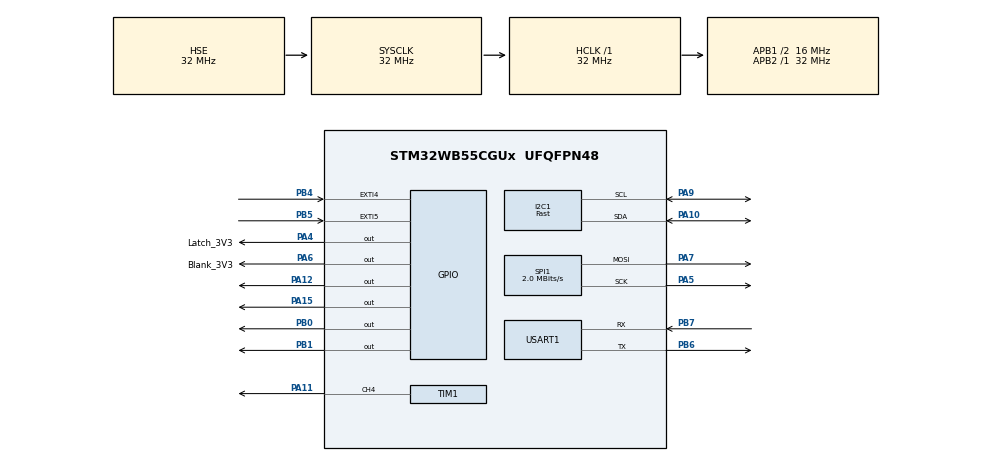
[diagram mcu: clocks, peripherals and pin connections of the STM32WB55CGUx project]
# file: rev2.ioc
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I2C1.I2C_Speed_Mode=I2C_Fast
I2C1.Timing=0x0010061A
LPTIM1.ClockPrescaler=LPTIM_PRESCALER_DIV128
Mcu.Family=STM32WB
Mcu.Name=STM32WB55CGUx
Mcu.Package=UFQFPN48
NVIC.EXTI4_IRQn=true\:0\:0\:false\:false\:true\:true\:true
NVIC.EXTI9_5_IRQn=true\:0\:0\:false\:false\:true\:true\:true
NVIC.HSEM_IRQn=true\:0\:0\:false\:false\:true\:false\:true
NVIC.I2C1_ER_IRQn=true\:0\:0\:false\:false\:true\:true\:true
NVIC.I2C1_EV_IRQn=true\:0\:0\:false\:false\:true\:true\:true
NVIC.IPCC_C1_RX_IRQn=true\:0\:0\:false\:false\:true\:true\:true
NVIC.IPCC_C1_TX_IRQn=true\:0\:0\:false\:false\:true\:true\:true
NVIC.LPTIM1_IRQn=true\:1\:0\:true\:false\:true\:true\:true
NVIC.LPTIM2_IRQn=true\:0\:0\:false\:false\:true\:true\:true
NVIC.PriorityGroup=NVIC_PRIORITYGROUP_4
NVIC.RTC_Alarm_IRQn=true\:0\:0\:false\:false\:true\:true\:true
NVIC.RTC_WKUP_IRQn=true\:0\:0\:false\:false\:true\:true\:true
NVIC.SPI1_IRQn=true\:0\:0\:false\:false\:true\:true\:true
NVIC.TIM1_TRG_COM_TIM17_IRQn=true\:0\:0\:false\:false\:true\:true\:true
NVIC.TIM1_UP_TIM16_IRQn=true\:0\:0\:false\:false\:true\:true\:true
NVIC.TIM2_IRQn=true\:0\:0\:false\:false\:true\:true\:true
NVIC.USART1_IRQn=true\:0\:0\:false\:false\:true\:true\:true
OSC_IN.Mode=HSE-External-Oscillator
OSC_IN.Signal=RCC_OSC_IN
OSC_OUT.Mode=HSE-External-Oscillator
OSC_OUT.Signal=RCC_OSC_OUT
PA10.Mode=I2C
PA10.Signal=I2C1_SDA
PA11.Signal=S_TIM1_CH4
PA12.Signal=GPIO_Output
PA15.Signal=GPIO_Output
PA4.GPIO_Label=Latch_3V3
PA4.Signal=GPIO_Output
PA5.Mode=TX_Only_Simplex_Unidirect_Master
PA5.Signal=SPI1_SCK
PA6.GPIO_Label=Blank_3V3
PA6.Signal=GPIO_Output
PA7.Mode=TX_Only_Simplex_Unidirect_Master
PA7.Signal=SPI1_MOSI
PA9.Mode=I2C
PA9.Signal=I2C1_SCL
PB0.Signal=GPIO_Output
PB1.Signal=GPIO_Output
PB4.GPIO_PuPd=GPIO_PULLDOWN
PB4.Signal=GPXTI4
PB5.GPIO_PuPd=GPIO_PULLDOWN
PB5.Signal=GPXTI5
PB6.Mode=Asynchronous
PB6.Signal=USART1_TX
PB7.Mode=Asynchronous
PB7.Signal=USART1_RX
PC14-OSC32_IN.Mode=LSE-External-Oscillator
PC14-OSC32_IN.Signal=RCC_OSC32_IN
PC15-OSC32_OUT.Mode=LSE-External-Oscillator
PC15-OSC32_OUT.Signal=RCC_OSC32_OUT
ProjectManager.HeapSize=0x200
ProjectManager.StackSize=0x400
ProjectManager.TargetToolchain=STM32CubeIDE
RCC.ADCFreq_Value=128000000
RCC.AHBFreq_Value=32000000
RCC.APB1CLKDivider=RCC_HCLK_DIV2
RCC.APB1Freq_Value=16000000
RCC.APB1TimFreq_Value=32000000
RCC.APB2Freq_Value=32000000
RCC.APB2TimFreq_Value=32000000
RCC.APB3Freq_Value=16000000
RCC.CortexFreq_Value=32000000
RCC.HCLKFreq_Value=32000000
RCC.HSE_VALUE=32000000
RCC.HSI48_VALUE=48000000
RCC.HSI_VALUE=16000000
RCC.MSIClockRange=RCC_MSIRANGE_10
RCC.RFWKPClockSelection=RCC_RFWKPCLKSOURCE_LSE
RCC.RTCClockSelection=RCC_RTCCLKSOURCE_LSE
RCC.SYSCLKFreq_VALUE=32000000
RCC.SYSCLKSource=RCC_SYSCLKSOURCE_HSE
RCC.USBFreq_Value=128000000
RCC.VCOOutputFreq_Value=256000000
RF1.Mode=RF1_Activate
RF1.Signal=RF_RF1
RTC.Alarm-Alarm\ A=RTC_ALARM_A
RTC.Alarm_B-Alarm\ B=RTC_ALARM_B
RTC.WakeUpClock-WakeUp=RTC_WAKEUPCLOCK_RTCCLK_DIV16
SH.S_TIM1_CH4.0=TIM1_CH4,PWM Generation4 CH4
SPI1.BaudRatePrescaler=SPI_BAUDRATEPRESCALER_16
SPI1.CLKPhase=SPI_PHASE_2EDGE
SPI1.CLKPolarity=SPI_POLARITY_LOW
SPI1.CalculateBaudRate=2.0 MBits/s
SPI1.DataSize=SPI_DATASIZE_16BIT
SPI1.Direction=SPI_DIRECTION_2LINES
SPI1.Mode=SPI_MODE_MASTER
SPI1.VirtualType=VM_MASTER
STM32_WPAN.CUSTOM_P2P_SERVER=Disabled
STM32_WPAN.CUSTOM_TEMPLATE=Enabled
TIM1.Channel-PWM\ Generation4\ CH4=TIM_CHANNEL_4
USART1.VirtualMode-Asynchronous=VM_ASYNC
VP_HSEM_VS_HSEM.Mode=HSEM_Activate
VP_IPCC_VS_IPCC.Mode=IPCC_Activate
VP_LPTIM1_VS_LPTIM_counterModeInternalClock.Mode=Counts__internal_clock_event_00
VP_LPTIM2_VS_LPTIM_counterModeInternalClock.Mode=Counts__internal_clock_event_00
VP_RTC_VS_RTC_Activate.Mode=RTC_Enabled
VP_RTC_VS_RTC_Alarm_A_Intern.Mode=Alarm A
VP_RTC_VS_RTC_Alarm_B_Intern.Mode=Alarm B
VP_RTC_VS_RTC_Calendar.Mode=RTC_Calendar
VP_RTC_VS_RTC_WakeUp_intern.Mode=WakeUp
VP_SEQUENCER_VS_SEQUENCER.Mode=SEQUENCER_Enabled
VP_STM32_WPAN_VS_BLE_HOST.Mode=STM32_WPAN_Enabled
VP_TIM1_VS_ClockSourceINT.Mode=Internal
VP_TIM2_VS_ClockSourceINT.Mode=Internal
VP_TINY_LPM_VS_TINY_LPM.Mode=TINY_LPM_Enabled
board=custom

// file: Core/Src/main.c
/* USER CODE BEGIN Header */
/**
  ******************************************************************************
  * @file           : main.c
  * @brief          : Main program body
  ******************************************************************************
  * @attention
  *
  * <h2><center>&copy; Copyright (c) 2021 STMicroelectronics.
  * All rights reserved.</center></h2>
  *
  * This software component is licensed by ST under BSD 3-Clause license,
  * the "License"; You may not use this file except in compliance with the
  * License. You may obtain a copy of the License at:
  *                        opensource.org/licenses/BSD-3-Clause
  *
  ******************************************************************************
  */
/* USER CODE END Header */
#include "main.h"
#include "i2c.h"
#include "ipcc.h"
#include "lptim.h"
#include "rf.h"
#include "rtc.h"
#include "spi.h"
#include "tim.h"
#include "usart.h"
#include "gpio.h"

/* USER CODE BEGIN Includes */
#include "stm32wbxx_ll_rcc.h"
/* USER CODE END Includes */

/* USER CODE BEGIN PV */
bool bkup_domain_restart_needed = true;
/* USER CODE END PV */

void SystemClock_Config(void);

int main(void)
{

  /* MCU Configuration--------------------------------------------------------*/

  /* Reset of all peripherals, Initializes the Flash interface and the Systick. */
  HAL_Init();
  /* Config code for STM32_WPAN (HSE Tuning must be done before system clock configuration) */
  MX_APPE_Config();

  /* Configure the system clock */
  SystemClock_Config();

  /* IPCC initialisation */
   MX_IPCC_Init();

  /* Initialize all configured peripherals */
  MX_GPIO_Init();
  MX_RF_Init();
  MX_RTC_Init();
  MX_SPI1_Init();
  MX_TIM2_Init();
  MX_LPTIM1_Init();
  MX_USART1_UART_Init();
  MX_LPTIM2_Init();
  MX_TIM1_Init();
  MX_I2C1_Init();

  /* Init code for STM32_WPAN */
  MX_APPE_Init();
  /* Infinite loop */
  while (1)
  {
    MX_APPE_Process();

  }
}

void SystemClock_Config(void)
{
  RCC_OscInitTypeDef RCC_OscInitStruct = {0};
  RCC_ClkInitTypeDef RCC_ClkInitStruct = {0};
  RCC_PeriphCLKInitTypeDef PeriphClkInitStruct = {0};

#if (NIXIE_FORCE_BACKUP_DOMAIN_RESET == 0)
  if(LL_RCC_LSE_IsEnabled() && LL_RCC_LSE_IsReady() && LL_RCC_IsEnabledRTC())
  {
    bkup_domain_restart_needed = false;
  }
#endif

  /** Configure LSE Drive Capability
  */
  HAL_PWR_EnableBkUpAccess();
  if(bkup_domain_restart_needed)
  {
    __HAL_RCC_LSEDRIVE_CONFIG(RCC_LSEDRIVE_LOW);
  }
  /** Configure the main internal regulator output voltage
  */
  __HAL_PWR_VOLTAGESCALING_CONFIG(PWR_REGULATOR_VOLTAGE_SCALE1);
  /** Initializes the RCC Oscillators according to the specified parameters
  * in the RCC_OscInitTypeDef structure.
  */
  RCC_OscInitStruct.OscillatorType = RCC_OSCILLATORTYPE_HSI|RCC_OSCILLATORTYPE_HSE
                              |RCC_OSCILLATORTYPE_LSE;
  RCC_OscInitStruct.HSEState = RCC_HSE_ON;
  RCC_OscInitStruct.LSEState = RCC_LSE_ON;
  RCC_OscInitStruct.HSIState = RCC_HSI_ON;
  RCC_OscInitStruct.HSICalibrationValue = RCC_HSICALIBRATION_DEFAULT;
  RCC_OscInitStruct.PLL.PLLState = RCC_PLL_NONE;
  if (!bkup_domain_restart_needed)
  {
    RCC_OscInitStruct.OscillatorType &= ~RCC_OSCILLATORTYPE_LSE;
  }
  if (HAL_RCC_OscConfig(&RCC_OscInitStruct) != HAL_OK)
  {
    Error_Handler();
  }
  if (!bkup_domain_restart_needed)
  {
    RCC_OscInitStruct.OscillatorType |= RCC_OSCILLATORTYPE_LSE;
  }

  /** Configure the SYSCLKSource, HCLK, PCLK1 and PCLK2 clocks dividers
  */
  RCC_ClkInitStruct.ClockType = RCC_CLOCKTYPE_HCLK4|RCC_CLOCKTYPE_HCLK2
                              |RCC_CLOCKTYPE_HCLK|RCC_CLOCKTYPE_SYSCLK
                              |RCC_CLOCKTYPE_PCLK1|RCC_CLOCKTYPE_PCLK2;
  RCC_ClkInitStruct.SYSCLKSource = RCC_SYSCLKSOURCE_HSE;
  RCC_ClkInitStruct.AHBCLKDivider = RCC_SYSCLK_DIV1;
  RCC_ClkInitStruct.APB1CLKDivider = RCC_HCLK_DIV2;
  RCC_ClkInitStruct.APB2CLKDivider = RCC_HCLK_DIV1;
  RCC_ClkInitStruct.AHBCLK2Divider = RCC_SYSCLK_DIV1;
  RCC_ClkInitStruct.AHBCLK4Divider = RCC_SYSCLK_DIV1;

  if (HAL_RCC_ClockConfig(&RCC_ClkInitStruct, FLASH_LATENCY_1) != HAL_OK)
  {
    Error_Handler();
  }
  /** Initializes the peripherals clocks
  */
  PeriphClkInitStruct.PeriphClockSelection = RCC_PERIPHCLK_SMPS|RCC_PERIPHCLK_RFWAKEUP
                              |RCC_PERIPHCLK_RTC|RCC_PERIPHCLK_USART1
                              |RCC_PERIPHCLK_LPTIM1|RCC_PERIPHCLK_LPTIM2
                              |RCC_PERIPHCLK_I2C1;
  PeriphClkInitStruct.Usart1ClockSelection = RCC_USART1CLKSOURCE_PCLK2;
  PeriphClkInitStruct.I2c1ClockSelection = RCC_I2C1CLKSOURCE_PCLK1;
  PeriphClkInitStruct.Lptim1ClockSelection = RCC_LPTIM1CLKSOURCE_PCLK1;
  PeriphClkInitStruct.Lptim2ClockSelection = RCC_LPTIM2CLKSOURCE_PCLK;
  PeriphClkInitStruct.RTCClockSelection = RCC_RTCCLKSOURCE_LSE;
  PeriphClkInitStruct.RFWakeUpClockSelection = RCC_RFWKPCLKSOURCE_LSE;
  PeriphClkInitStruct.SmpsClockSelection = RCC_SMPSCLKSOURCE_HSI;
  PeriphClkInitStruct.SmpsDivSelection = RCC_SMPSCLKDIV_RANGE1;
  if(!bkup_domain_restart_needed)
  {
    PeriphClkInitStruct.PeriphClockSelection &= ~RCC_PERIPHCLK_RTC;
  }
  if (HAL_RCCEx_PeriphCLKConfig(&PeriphClkInitStruct) != HAL_OK)
  {
    Error_Handler();
  }
  if(!bkup_domain_restart_needed)
  {
    PeriphClkInitStruct.PeriphClockSelection |= RCC_PERIPHCLK_RTC;
  }
}

void Error_Handler(void)
{
  __disable_irq();
  while (1)
  {
  }
}

/************************ (C) COPYRIGHT STMicroelectronics *****END OF FILE****/
